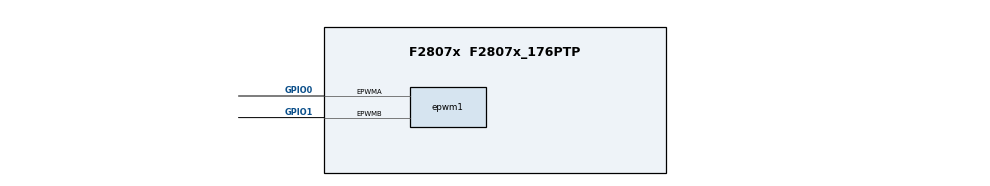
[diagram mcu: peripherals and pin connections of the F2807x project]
/**
 * @cliArgs --device "F2807x" --part "F2807x_176PTP" --package "F2807x_176PTP" --context "system"
 */

/**
 * Import the modules used in this configuration.
 */
const epwm       = scripting.addModule("/driverlib/epwm.js", {}, false);
const epwm1      = epwm.addInstance();
const inputxbar  = scripting.addModule("/driverlib/inputxbar.js", {}, false);
const inputxbar1 = inputxbar.addInstance();

/**
 * Write custom configuration values to the imported modules.
 */


epwm1.$name                 = "myEPWM1";
epwm1.epwm.$assign          = "EPWM1";
epwm1.epwm.epwmaPin.$assign = "GPIO0";
epwm1.epwm.epwmbPin.$assign = "GPIO1";

inputxbar1.$name          = "myINPUTXBAR5";
inputxbar1.inputsUsed     = ["inputxbar5Gpio","inputxbar6Gpio"];
inputxbar1.inputxbar5Gpio = "GPIO56";
inputxbar1.inputxbar6Gpio = "GPIO56";
